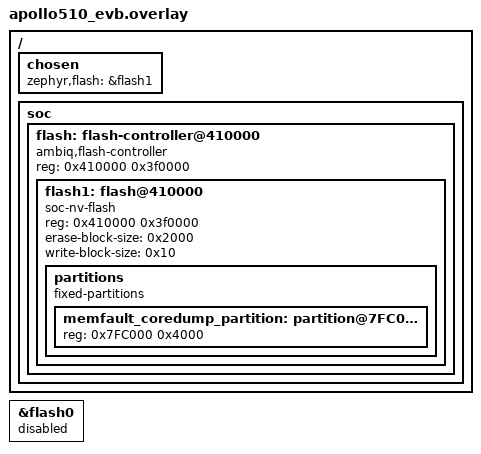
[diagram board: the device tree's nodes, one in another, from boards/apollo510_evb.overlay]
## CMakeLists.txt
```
# Zephyr Example Application

cmake_minimum_required(VERSION 3.20.0)

# The default board for this example is the mps2/an385, but can be
# overridden by passing --board=<board> to west or -DBOARD=<board> to cmake
set(BOARD mps2/an385)

# Select version-specific config overlays before Zephyr is loaded
file(READ "$ENV{ZEPHYR_BASE}/VERSION" _zephyr_version_file)
string(REGEX MATCH "VERSION_MAJOR = ([0-9]+)" _ ${_zephyr_version_file})
set(_zephyr_major ${CMAKE_MATCH_1})
string(REGEX MATCH "VERSION_MINOR = ([0-9]+)" _ ${_zephyr_version_file})
set(_zephyr_minor ${CMAKE_MATCH_1})
string(REGEX MATCH "PATCHLEVEL = ([0-9]+)" _ ${_zephyr_version_file})
set(_zephyr_patch ${CMAKE_MATCH_1})

if("${_zephyr_major}.${_zephyr_minor}.${_zephyr_patch}" VERSION_GREATER_EQUAL "3.4.0")
  set(OVERLAY_CONFIG "${OVERLAY_CONFIG};${CMAKE_CURRENT_SOURCE_DIR}/overlays/zephyr-v3.4.conf")
endif()

find_package(Zephyr REQUIRED HINTS $ENV{ZEPHYR_BASE})

target_sources(app PRIVATE
  src/cdr.c
  src/main.c
  src/metrics.c
)
zephyr_include_directories(config)
project(qemu-app LANGUAGES C VERSION 1.0.0)

# Generate a git hash that's used as part of the software_version, eg
# 1.0.0+12345678. Permit overriding at command line for CI builds.
if (NOT DEFINED ZEPHYR_MEMFAULT_EXAMPLE_GIT_SHA1)
  EXECUTE_PROCESS(
    WORKING_DIRECTORY ${CMAKE_CURRENT_SOURCE_DIR}
    COMMAND git rev-parse --short HEAD
    RESULT_VARIABLE commit_sha1
    OUTPUT_VARIABLE ZEPHYR_MEMFAULT_EXAMPLE_GIT_SHA1
    OUTPUT_STRIP_TRAILING_WHITESPACE
    COMMAND_ERROR_IS_FATAL ANY
  )
endif()

zephyr_compile_definitions(
  ZEPHYR_MEMFAULT_EXAMPLE_GIT_SHA1=\"${ZEPHYR_MEMFAULT_EXAMPLE_GIT_SHA1}\"
)

zephyr_compile_options(--param=min-pagesize=0x1000)

# For Zephyr >=3.0.0,<3.6.0, explicitly enable -Werror
if (${KERNEL_VERSION_MAJOR}.${KERNEL_VERSION_MINOR}.${KERNEL_PATCHLEVEL} VERSION_GREATER_EQUAL 3.0.0 AND
    ${KERNEL_VERSION_MAJOR}.${KERNEL_VERSION_MINOR}.${KERNEL_PATCHLEVEL} VERSION_LESS 3.6.0)
  zephyr_compile_options(-Werror)
endif()
```

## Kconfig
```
# Application Kconfig file
#
# This is loaded when building this directory with west.
menu "Memfault Example Application Configuration"

config ZEPHYR_MEMFAULT_EXAMPLE_AUTO_SETTINGS
    bool
    default y
    # Force on CONFIG_GPIO if the led0 alias is enabled
    select GPIO if $(dt_alias_enabled,led0)
    help
      Non-user-settable configuration options for the example app.

config ZEPHYR_MEMFAULT_EXAMPLE_THREAD_TOGGLE
    bool "Example thread create + abort toggling every 10 seconds"
    default n
    help
      Enables creating and aborting an example thread every 10 seconds in the
      example app

config ZEPHYR_MEMFAULT_EXAMPLE_METRICS
    bool "Use metrics to monitor memory usage and execution time in the example app"
    default y
    depends on MEMFAULT && MEMFAULT_HEAP_STATS
    depends on THREAD_STACK_INFO
    depends on THREAD_RUNTIME_STATS

config ZEPHYR_MEMFAULT_EXAMPLE_SOFTWARE_VERSION
    string "Software Version"
    default "1.0.0"
    help
      The software version to report to Memfault.

# Stub expressions, to support backwards compatibility with older Zephyr
# versions where these options were not available.
config COMPILER_WARNINGS_AS_ERRORS  # v3.6.0+
    bool "Treat warnings as errors"

config CRC  # v3.3.0+
    bool "Cyclic redundancy check (CRC) Support"

config BUILD_OUTPUT_META  # v3.0.0+
    bool "Create a build meta file"

endmenu

source "Kconfig.zephyr"
```

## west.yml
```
# West manifest for Memfault Example Application

manifest:
  self:
    path: qemu-app

  group-filter:
    # Disable the ambiq hal by default; it's compatible only with Zephyr v4.3.0.
    # To enable it, run:
    #   west config manifest.group-filter +ambiq
    #   west update
    - "-ambiq"

  remotes:
    - name: zephyrproject-rtos
      url-base: https://github.com/zephyrproject-rtos
    - name: memfault
      url-base: https://github.com/memfault

  projects:
    - name: zephyr
      remote: zephyrproject-rtos
      revision: v4.4.0
      import:
        # Limit the Zephyr modules to the required set
        name-allowlist:
          - cmsis
          - cmsis_6
          - picolibc
          - hal_ambiq
          - hal_nxp
          - hal_stm32

    # Override the hal_ambiq module to use our patched version, which supports
    # MRAM flash driver on Apollo510
    - name: hal_ambiq
      path: modules/hal/ambiq
      remote: memfault
      revision: zephyr-v4.3.0-apollo510-mram-patch
      groups:
        - ambiq

    - name: memfault-firmware-sdk
      path: modules/lib/memfault-firmware-sdk
      remote: memfault
      # Note: normally this would be pinned to a specific SDK tag instead of
      # master
      revision: master
```

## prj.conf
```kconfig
# This file contains selected Kconfig options for the application.

# Memfault configuration
CONFIG_MEMFAULT=y

# Enable UART console and shell for testing memfault
CONFIG_CONSOLE=y
CONFIG_UART_CONSOLE=y
CONFIG_SHELL=y

# This makes the qemu guest run closer to real time instead of super fast
CONFIG_QEMU_ICOUNT=n

CONFIG_LOG=y
# Using immediate mode to avoid dropping bursts of log messages, eg when running
# `mflt export` to dump base64-chunks to the console
CONFIG_LOG_MODE_IMMEDIATE=y
CONFIG_LOG_BACKEND_UART=y
# Disable shell log output to prevent duplicate logs, since UART backend is
# already enabled. Shell log backend enables later than UART backend, and won't
# show the boot splash messages, so it's simpler to just enable the UART
# backend. Note that the RTT backend is enabled by default- that's ok, and could
# be useful if the board doesn't have a UART available.
CONFIG_SHELL_LOG_BACKEND=n
# Disable logging of printk, to improve 'mflt export' performance under deferred
# logging mode.
CONFIG_LOG_PRINTK=n

# Enable heap stats explicitly. It's enabled by default when heap is enabled,
# see below, but in a default app, it won't be enabled because heap is disabled.
# For this reference example, we select it explicitly.
CONFIG_MEMFAULT_HEAP_STATS=y

# Increase the heap pool and main stack sizes for the example app. Setting a
# non-zero memory pool size is required for heap stats, otherwise there's no
# k_malloc used
CONFIG_HEAP_MEM_POOL_SIZE=4096
CONFIG_MAIN_STACK_SIZE=4096

# Enable Zephyr runtime asserts
CONFIG_ASSERT=y

# Enable Memfault Compact Logs
CONFIG_MEMFAULT_COMPACT_LOG=y

# Enable Memfault self test
CONFIG_MEMFAULT_SHELL_SELF_TEST=y
CONFIG_MEMFAULT_SHELL_SELF_TEST_COREDUMP_STORAGE=y

# Enable emulated RTC driver. Disabled by default because the RTC needs to be
# explicitly updated at runtime to wall clock time, otherwise it will print
# errors.
# CONFIG_RTC=y
# CONFIG_RTC_EMUL=y
# CONFIG_RTC_SHELL=y

# Enable warnings as errors
CONFIG_COMPILER_WARNINGS_AS_ERRORS=y  # v3.6.0+

# Enable Thread run-time stats
CONFIG_THREAD_RUNTIME_STATS=y

# Enable Zephyr CRC implementation, for demonstration purposes only. The
# Memfault SDK provides a built-in CRC-16 implementation used for Memfault chunk
# packets.
CONFIG_CRC=y  # v3.3.0+
```

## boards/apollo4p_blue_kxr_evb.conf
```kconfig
CONFIG_MEMFAULT_COREDUMP_STORAGE_AMBIQ_MRAM=y
```

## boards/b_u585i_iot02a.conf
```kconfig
CONFIG_MEMFAULT_COREDUMP_STORAGE_STM32U5_FLASH=y

# Needed for HWINFO
CONFIG_POWEROFF=y
```

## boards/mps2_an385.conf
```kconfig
CONFIG_MPU_STACK_GUARD=y
CONFIG_WATCHDOG=y
CONFIG_WDOG_CMSDK_APB_START_AT_BOOT=y

# This isn't actually needed- it just adds a reboot in the driver, and we wrap
# the NMI handler anyway, but there is a Kconfig dependency in the CMSDK APB
# watchdog driver so we are forced to include it.
CONFIG_RUNTIME_NMI=y

# Disable the hwinfo module. Enabled by default in the Zephyr port, but there is no
# hwinfo implementation for the QEMU target. Disabling it saves ~100B of code space.
CONFIG_HWINFO=n
```

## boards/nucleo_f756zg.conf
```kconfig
CONFIG_ADC=y
CONFIG_SENSOR=y
```

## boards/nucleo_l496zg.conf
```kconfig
CONFIG_BBRAM=y
CONFIG_BBRAM_SHELL=y
CONFIG_RTC=y
```

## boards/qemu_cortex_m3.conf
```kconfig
CONFIG_STACK_SENTINEL=y

# Disable the hwinfo module. Enabled by default in the Zephyr port, but there is no
# hwinfo implementation for the QEMU target. Disabling it saves ~100B of code space.
CONFIG_HWINFO=n
```

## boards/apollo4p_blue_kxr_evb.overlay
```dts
/*
 Adjust the fixed partitions in flash (MRAM) to add a 'memfault_coredump'
 partition for storing coredumps
*/

&flash0 {
	partitions {
		storage_partition: partition@1e4000 {
			label = "storage";
			reg = < 0x1e4000 0x2000 >;
		};
		memfault_coredump_partition: partition@1e6000 {
			reg = <0x1e6000 0x2000>;
		};
	};
};
```

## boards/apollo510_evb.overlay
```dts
/*
 Adjust the fixed partitions in flash (MRAM) to add a 'memfault_coredump'
 partition for storing coredumps
*/

/*
 Remove the standalone flash0 node, and replace it with a new one set as
 compatible with Ambiq flash driver
*/
&flash0 {
	status = "disabled";
};
/ {
	chosen {
		zephyr,flash = &flash1;
	};
	soc {
		flash: flash-controller@410000 {
			compatible = "ambiq,flash-controller";
			reg = < 0x410000 0x3f0000 >;
			#address-cells = < 0x1 >;
			#size-cells = < 0x1 >;

			flash1: flash@410000 {
				compatible = "soc-nv-flash";
				reg = < 0x410000 0x3f0000 >;
				erase-block-size = < 0x2000 >;
				write-block-size = < 0x10 >;

				partitions {
					compatible = "fixed-partitions";
					#address-cells = < 0x1 >;
					#size-cells = < 0x1 >;

					memfault_coredump_partition: partition@7FC000 {
						reg = < 0x7FC000 0x4000 >;
					};
				};
			};
		};
	};
};
```

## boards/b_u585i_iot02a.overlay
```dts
/*
 Adjust the fixed partitions in internal flash to add a
 'memfault_coredump_partition' for storing coredumps.
*/

&flash0 {
	partitions {
		storage_partition: partition@f0000 {
			label = "storage";
			reg = < 0xf0000 0x2000 >;
		};
		memfault_coredump_partition: partition@f2000 {
			label = "memfault_coredump_partition";
			reg = <0xf2000 0x2000>;
		};
	};
};
```

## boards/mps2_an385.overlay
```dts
/*
    Add emulated RTC device.
*/

/ {
	aliases {
		rtc = &rtc;
	};
	rtc: rtc {
		status = "okay";
		compatible = "zephyr,rtc-emul";
		alarms-count = <2>;
	};
};
```

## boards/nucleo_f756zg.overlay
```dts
/ {
	aliases {
		die-temp0 = &die_temp;
	};
};

&die_temp {
	status = "okay";
};

&adc1 {
	pinctrl-0 = <&adc1_in0_pa0>;
	pinctrl-names = "default";
	st,adc-prescaler = <4>;
	status = "okay";
};
```

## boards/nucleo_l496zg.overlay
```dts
/ {
	aliases {
		backup-register = &bbram;
	};
};

&bbram {
	status = "okay";
};
```

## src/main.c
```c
//! @file
//!
//! Copyright (c) Memfault, Inc.
//! See LICENSE for details
//!
//! Example app main

// clang-format off
#include "memfault/ports/zephyr/include_compatibility.h"
#include <stdlib.h>

#include MEMFAULT_ZEPHYR_INCLUDE(device.h)
#include MEMFAULT_ZEPHYR_INCLUDE(devicetree.h)
#include MEMFAULT_ZEPHYR_INCLUDE(drivers/gpio.h)
#include MEMFAULT_ZEPHYR_INCLUDE(kernel.h)
#include MEMFAULT_ZEPHYR_INCLUDE(logging/log.h)
#include MEMFAULT_ZEPHYR_INCLUDE(shell/shell.h)

#include "cdr.h"
#include "memfault/components.h"
#include "memfault/ports/zephyr/core.h"
// clang-format on

LOG_MODULE_REGISTER(main, LOG_LEVEL_INF);

#if CONFIG_ZEPHYR_MEMFAULT_EXAMPLE_METRICS
  //! Size of memory to allocate on main stack
  //! This requires a larger allocation due to the method used to measure stack usage
  #define STACK_ALLOCATION_SIZE (CONFIG_MAIN_STACK_SIZE >> 2)
  //! Size of memory to allocate on system heap
  #define HEAP_ALLOCATION_SIZE (CONFIG_HEAP_MEM_POOL_SIZE >> 3)
  //! Value to sleep for observing metrics changes
  #define METRICS_OBSERVE_PERIOD MEMFAULT_METRICS_HEARTBEAT_INTERVAL_SECS

//! Array of heap pointers
static void *heap_ptrs[4] = { NULL };
  #if defined(CONFIG_COMMON_LIBC_MALLOC)
    #define MALLOC_ALLOCATION_SIZE (CONFIG_COMMON_LIBC_MALLOC_ARENA_SIZE >> 3)
//! Array of malloc pointers
static void *malloc_ptrs[4] = { NULL };
  #endif

//! Keep a reference to the main thread for stack info
static struct k_thread *s_main_thread = NULL;
#endif  // CONFIG_ZEPHYR_MEMFAULT_EXAMPLE_METRICS

// Blink code taken from the zephyr/samples/basic/blinky example.
static void blink_forever(void) {
#if DT_NODE_HAS_PROP(DT_ALIAS(led0), gpios)
  /* 1000 msec = 1 sec */
  #define SLEEP_TIME_MS 1000

  /* The devicetree node identifier for the "led0" alias. */
  #define LED0_NODE DT_ALIAS(led0)

  static const struct gpio_dt_spec led = GPIO_DT_SPEC_GET(LED0_NODE, gpios);

  int ret = gpio_pin_configure_dt(&led, GPIO_OUTPUT_ACTIVE);
  if (ret < 0) {
    return;
  }

  while (1) {
    gpio_pin_toggle_dt(&led);
    k_msleep(SLEEP_TIME_MS);
  }
#else
  // no led on this board, just sleep forever
  k_sleep(K_FOREVER);
#endif
}

void memfault_platform_get_device_info(sMemfaultDeviceInfo *info) {
  *info = (sMemfaultDeviceInfo){
    .device_serial = "DEMOSERIAL",
    .software_type = "zephyr-app",
    .software_version =
      CONFIG_ZEPHYR_MEMFAULT_EXAMPLE_SOFTWARE_VERSION "+" ZEPHYR_MEMFAULT_EXAMPLE_GIT_SHA1,
    .hardware_version = CONFIG_BOARD,
  };
}

#if CONFIG_ZEPHYR_MEMFAULT_EXAMPLE_THREAD_TOGGLE
K_THREAD_STACK_DEFINE(test_thread_stack_area, 1024);
static struct k_thread test_thread;

static void prv_test_thread_function(void *arg0, void *arg1, void *arg2) {
  ARG_UNUSED(arg0);
  ARG_UNUSED(arg1);
  ARG_UNUSED(arg2);

  k_sleep(K_FOREVER);
}

static void prv_test_thread_work_handler(struct k_work *work) {
  ARG_UNUSED(work);

  static bool started = false;
  if (started) {
    LOG_INF("ending test_thread ❌");
    k_thread_abort(&test_thread);
    started = false;
  } else {
    LOG_INF("starting test_thread ✅");
    k_thread_create(&test_thread, test_thread_stack_area,
                    K_THREAD_STACK_SIZEOF(test_thread_stack_area), prv_test_thread_function, NULL,
                    NULL, NULL, 7, 0, K_FOREVER);
    k_thread_name_set(&test_thread, "test_thread");
    k_thread_start(&test_thread);
    started = true;
  }
}
K_WORK_DEFINE(s_test_thread_work, prv_test_thread_work_handler);

//! Timer handlers run from an ISR so we dispatch the heartbeat job to the
//! worker task
static void prv_test_thread_timer_expiry_handler(struct k_timer *dummy) {
  k_work_submit(&s_test_thread_work);
}
K_TIMER_DEFINE(s_test_thread_timer, prv_test_thread_timer_expiry_handler, NULL);

static void prv_init_test_thread_timer(void) {
  k_timer_start(&s_test_thread_timer, K_SECONDS(10), K_SECONDS(10));

  // fire one time right away
  k_work_submit(&s_test_thread_work);
}
#else
static void prv_init_test_thread_timer(void) { }
#endif  // CONFIG_ZEPHYR_MEMFAULT_EXAMPLE_THREAD_TOGGLE

#if CONFIG_ZEPHYR_MEMFAULT_EXAMPLE_METRICS

  #if defined(CONFIG_INIT_STACKS) && defined(CONFIG_THREAD_STACK_INFO)
//! Helper function to collect metric value on main thread stack usage.
static void prv_collect_main_thread_stack_free(void) {
  if (s_main_thread == NULL) {
    return;
  }

  size_t unused = 0;
  int rc = k_thread_stack_space_get(s_main_thread, &unused);
  if (rc == 0) {
    rc = MEMFAULT_METRIC_SET_UNSIGNED(MainStack_MinBytesFree, unused);
    if (rc) {
      LOG_ERR("Error[%d] setting MainStack_MinBytesFree", rc);
    }
  } else {
    LOG_ERR("Error getting thread stack usage[%d]", rc);
  }
}
  #endif  // defined(CONFIG_INIT_STACKS) && defined(CONFIG_THREAD_STACK_INFO)

static void prv_collect_main_thread_run_stats(void) {
  static uint64_t s_prev_main_thread_cycles = 0;
  static uint64_t s_prev_cpu_all_cycles = 0;

  if (s_main_thread == NULL) {
    return;
  }

  k_thread_runtime_stats_t rt_stats_main = { 0 };
  k_thread_runtime_stats_t rt_stats_all = { 0 };

  k_thread_runtime_stats_get(s_main_thread, &rt_stats_main);
  k_thread_runtime_stats_all_get(&rt_stats_all);

  // Calculate difference since last heartbeat
  uint64_t current_main_thread_cycles = rt_stats_main.execution_cycles - s_prev_main_thread_cycles;
  // Note: execution_cycles = idle + non-idle, total_cycles = non-idle
  uint64_t current_cpu_total_cycles = rt_stats_all.execution_cycles - s_prev_cpu_all_cycles;

  // Calculate percent of main thread execution vs total CPU time. The metric is
  // defined as scaled *10- the value is recorded as percent * 10 (1000), and
  // will be scaled down on ingestion to a float.
  if (current_cpu_total_cycles > 0) {
    uint32_t main_thread_cpu_time = (current_main_thread_cycles * 1000) / current_cpu_total_cycles;
    MEMFAULT_METRIC_SET_UNSIGNED(cpu_usage_main_pct, main_thread_cpu_time);
  }

  // Update previous values
  s_prev_main_thread_cycles = current_main_thread_cycles;
  s_prev_cpu_all_cycles = current_cpu_total_cycles;
}

//! Shell function to exercise example memory metrics
//!
//! This function demonstrates the change in stack and heap memory metrics
//! as memory is allocated and deallocated from these regions.
//!
//! @warning This code uses `memfault_metrics_heartbeat_debug_trigger` which is not intended
//! to be used in production code. This functions use here is solely to demonstrate the metrics
//! values changing. Production applications should rely on the heartbeat timer to trigger
//! collection
static int prv_run_example_memory_metrics(const struct shell *shell, size_t argc, char **argv) {
  ARG_UNUSED(shell);
  ARG_UNUSED(argc);
  ARG_UNUSED(argv);

  if (s_main_thread == NULL) {
    return 0;
  }

  // Next two loops demonstrate heap usage metrics
  for (size_t i = 0; i < ARRAY_SIZE(heap_ptrs); i++) {
    heap_ptrs[i] = k_malloc(HEAP_ALLOCATION_SIZE);
  }
  #if defined(CONFIG_COMMON_LIBC_MALLOC)
  for (size_t i = 0; i < ARRAY_SIZE(malloc_ptrs); i++) {
    malloc_ptrs[i] = malloc(MALLOC_ALLOCATION_SIZE);
  }
  #endif

  // Collect data after allocation
  memfault_metrics_heartbeat_debug_trigger();

  for (size_t i = 0; i < ARRAY_SIZE(heap_ptrs); i++) {
    k_free(heap_ptrs[i]);
    heap_ptrs[i] = NULL;
  }
  #if defined(CONFIG_COMMON_LIBC_MALLOC)
  for (size_t i = 0; i < ARRAY_SIZE(malloc_ptrs); i++) {
    free(malloc_ptrs[i]);
    malloc_ptrs[i] = NULL;
  }
  #endif

  // Collect data after deallocation
  memfault_metrics_heartbeat_debug_trigger();
  return 0;
}

SHELL_CMD_REGISTER(memory_metrics, NULL, "Collects runtime memory metrics from application",
                   prv_run_example_memory_metrics);

  #if defined(CONFIG_INIT_STACKS) && defined(CONFIG_THREAD_STACK_INFO)
//! Callback to collect stack usage for specific threads
static void prv_collect_thread_stack_usage_cb(const struct k_thread *thread, void *user_data) {
  // table mapping thread names to metric IDs
  static const struct {
    const char *name;
    MemfaultMetricId id;
  } threads[] = {
    { "shell_uart", MEMFAULT_METRICS_KEY(shell_uart_stack_free_bytes) },
  };

  // scan for a matching thread name
  for (size_t i = 0; i < ARRAY_SIZE(threads); i++) {
    if (strncmp(thread->name, threads[i].name, CONFIG_THREAD_MAX_NAME_LEN) == 0) {
      // get the stack usage and record in the matching metric id
      size_t stack_free_bytes;
      k_thread_stack_space_get(thread, &stack_free_bytes);
      memfault_metrics_heartbeat_set_unsigned(threads[i].id, stack_free_bytes);
    }
  }
}
  #endif  // defined(CONFIG_INIT_STACKS) && defined(CONFIG_THREAD_STACK_INFO)

// Override function to collect the app metric MainStack_MinBytesFree
// and print current metric values
void memfault_metrics_heartbeat_collect_data(void) {
  prv_collect_main_thread_run_stats();

  #if defined(CONFIG_INIT_STACKS) && defined(CONFIG_THREAD_STACK_INFO)
  prv_collect_main_thread_stack_free();
  k_thread_foreach(prv_collect_thread_stack_usage_cb, NULL);
  #endif

  memfault_metrics_heartbeat_debug_print();
}

//! Helper function to demonstrate changes in stack metrics
static void prv_run_stack_metrics_example(void) {
  volatile uint8_t stack_array[STACK_ALLOCATION_SIZE];
  memset((uint8_t *)stack_array, 0, STACK_ALLOCATION_SIZE);
}
#endif  // CONFIG_ZEPHYR_MEMFAULT_EXAMPLE_METRICS

#if defined(CONFIG_MEMFAULT_FAULT_HANDLER_RETURN)
  #include MEMFAULT_ZEPHYR_INCLUDE(fatal.h)
void k_sys_fatal_error_handler(unsigned int reason, const z_arch_esf_t *esf) {
  printk("User fatal handler invoked with reason: %d. Rebooting!\n", reason);
  memfault_platform_reboot();
}
#endif

static int prv_metrics_session(const struct shell *shell, size_t argc, char **argv) {
  const char *cmd_name_string = "UNKNOWN";
  if (argc > 1) {
    cmd_name_string = argv[1];
  }

  shell_print(shell, "Executing a test metrics session named 'cli'\n");

  MEMFAULT_METRICS_SESSION_START(cli);
  // API v1
  // MEMFAULT_METRIC_SET_STRING(cli_cmd_name, cmd_name_string);
  // API v2
  MEMFAULT_METRIC_SESSION_SET_STRING(cmd_name, cli, cmd_name_string);
  MEMFAULT_METRICS_SESSION_END(cli);

  return 0;
}

SHELL_CMD_REGISTER(metrics_session, NULL, "Trigger a one-time metrics session for testing",
                   prv_metrics_session);

static int prv_session_crash(const struct shell *shell, size_t argc, char **argv) {
  ARG_UNUSED(shell);
  ARG_UNUSED(argc);
  ARG_UNUSED(argv);

  LOG_ERR("Triggering crash");

  MEMFAULT_METRICS_SESSION_START(cli);

  MEMFAULT_ASSERT(0);

  return 0;
}

SHELL_CMD_REGISTER(session_crash, NULL, "session crash", prv_session_crash);

#if defined(CONFIG_BBRAM)
  #include <zephyr/drivers/bbram.h>

void memfault_reboot_tracking_load(sMemfaultRebootTrackingStorage *dst) {
  // restore reboot tracking from bbram_read

  // clear the destination buffer- if the bbram restore doesn't work, we won't
  // have reboot tracking data.
  memset(dst, 0, sizeof(*dst));

  const struct device *const dev = DEVICE_DT_GET(DT_NODELABEL(bbram));
  for (size_t i = 0; i < sizeof(*dst) / 4; i++) {
    bbram_read(dev, 4 * i, 4, &dst->data[4 * i]);
  }
}

void memfault_reboot_tracking_save(const sMemfaultRebootTrackingStorage *src) {
  // now back up reboot tracking to RTC backup regs
  const struct device *const dev = DEVICE_DT_GET(DT_NODELABEL(bbram));
  for (size_t i = 0; i < sizeof(*src) / 4; i++) {
    bbram_write(dev, 4 * i, 4, &src->data[4 * i]);
  }
}
#endif  // defined(CONFIG_BBRAM)

static int prv_log_overflow(const struct shell *shell, size_t argc, char **argv) {
  // get log line count from command line
  int log_line_count = 0;
  if (argc > 1) {
    log_line_count = strtoul(argv[1], NULL, 0);
  }

  for (int i = 0; i < log_line_count; i++) {
    LOG_INF("Log line %d", i);
  }

  shell_print(shell, "Dropped/recorded log lines: %d/%d", memfault_log_get_dropped_count(),
              memfault_log_get_recorded_count());

  return 0;
}

SHELL_CMD_REGISTER(log_overflow, NULL, "generate a number of log lines", prv_log_overflow);

#include "memfault/core/heap_stats_impl.h"
static int prv_calloc_test(const struct shell *shell, size_t argc, char **argv) {
  (void)argc;
  (void)argv;
  shell_print(shell, "before: in_use=%u max_in_use=%u", g_memfault_heap_stats.in_use_block_count,
              g_memfault_heap_stats.max_in_use_block_count);
  void *ptr = k_calloc(4, 16);
  shell_print(shell, "k_calloc(4, 16) -> %p", ptr);
  shell_print(shell, "after: in_use=%u max_in_use=%u", g_memfault_heap_stats.in_use_block_count,
              g_memfault_heap_stats.max_in_use_block_count);
  k_free(ptr);
  return 0;
}
SHELL_CMD_REGISTER(calloc_test, NULL, "temp test of k_calloc heap stats tracking", prv_calloc_test);

#if !defined(CONFIG_MEMFAULT_CRC16_BUILTIN)
  #include MEMFAULT_ZEPHYR_INCLUDE(sys/crc.h)

uint16_t memfault_crc16_compute(uint16_t crc_initial_value, const void *data,
                                size_t data_len_bytes) {
  return crc16_itu_t(crc_initial_value, data, data_len_bytes);
}
#endif

#if defined(CONFIG_MEMFAULT_PLATFORM_TIME_SINCE_BOOT_CUSTOM)
uint64_t memfault_platform_get_time_since_boot_ms(void) {
  // Simple custom implementation, identical to the default one, to demonstrate
  // how to override the time since boot function.
  return k_uptime_get();
}
#endif

#if defined(CONFIG_WDOG_CMSDK_APB_START_AT_BOOT)
  #include MEMFAULT_ZEPHYR_INCLUDE(drivers/watchdog.h)
// Watchdog feed timer
static void prv_watchdog_feed_timer_handler(struct k_timer *dummy) {
  ARG_UNUSED(dummy);
  const struct device *const wdt = DEVICE_DT_GET(DT_ALIAS(watchdog0));
  // the CMSDK WDOG doesn't use a channel, pass 0
  wdt_feed(wdt, 0);
}
K_TIMER_DEFINE(s_watchdog_feed_timer, prv_watchdog_feed_timer_handler, NULL);

static int prv_start_watchdog_feed_timer() {
  // Start the watchdog feed timer to prevent the watchdog from resetting the system
  k_timer_start(&s_watchdog_feed_timer, K_MSEC(100), K_MSEC(100));
  return 0;
}

SYS_INIT(prv_start_watchdog_feed_timer, APPLICATION, CONFIG_KERNEL_INIT_PRIORITY_DEFAULT);
#endif  // CONFIG_WDOG_CMSDK_APB_START_AT_BOOT

int main(void) {
  LOG_INF("👋 Memfault Demo App! Board %s\n", CONFIG_BOARD);
  memfault_device_info_dump();

  memfault_cdr_register_source(&g_custom_data_recording_source);

#if !defined(CONFIG_MEMFAULT_RECORD_REBOOT_ON_SYSTEM_INIT)
  memfault_zephyr_collect_reset_info();
#endif

#if CONFIG_ZEPHYR_MEMFAULT_EXAMPLE_METRICS
  s_main_thread = k_current_get();

  // @warning This code uses `memfault_metrics_heartbeat_debug_trigger` which is not intended
  // to be used in production code. This functions use here is solely to demonstrate the metrics
  // values changing. Production applications should rely on the heartbeat timer to trigger
  // collection

  // Collect a round of metrics to show initial stack usage
  memfault_metrics_heartbeat_debug_trigger();

  prv_run_stack_metrics_example();

  // Collect another round to show change in stack metrics
  memfault_metrics_heartbeat_debug_trigger();
#endif

  prv_init_test_thread_timer();

  blink_forever();

  return 0;
}
```

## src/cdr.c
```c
//! @file
//!
//! Copyright (c) Memfault, Inc.
//! See LICENSE for details
//!
//! Sample CDR implementation. See https://mflt.io/custom-data-recordings for
//! more information

// clang-format off
#include "memfault/ports/zephyr/include_compatibility.h"

#include MEMFAULT_ZEPHYR_INCLUDE(logging/log.h)
#include MEMFAULT_ZEPHYR_INCLUDE(shell/shell.h)

#include "memfault/components.h"
// clang-format on

LOG_MODULE_REGISTER(cdr);

// Only read the CDR payload when this is set
static bool s_cdr_ready_to_send = false;
// keep track of the offset into the CDR data; the packetizer may call
// repeatedly depending on chunk size constraints
static size_t s_cdr_read_offset = 0;

// set of MIME types for this payload
static const char *mimetypes[] = { MEMFAULT_CDR_TEXT };

// the actual payload is just a simple string in this example
static const char cdr_payload[] = "hello cdr!";

// the CDR metadata structure
static sMemfaultCdrMetadata s_cdr_metadata = {
  .start_time = {
    .type = kMemfaultCurrentTimeType_Unknown,
  },
  .mimetypes = mimetypes,
  .num_mimetypes = MEMFAULT_ARRAY_SIZE(mimetypes),

  // in this case, the data size is fixed. typically it would be set in the
  // prv_has_cdr_cb() function, and likely variable size
  .data_size_bytes = sizeof(cdr_payload) - 1,
  .duration_ms = 0,

  .collection_reason = "example cdr upload",
};

// called to see if there's any data available; uses the *metadata output to set
// the header fields in the chunked message sent to Memfault
static bool prv_has_cdr_cb(sMemfaultCdrMetadata *metadata) {
  *metadata = s_cdr_metadata;
  return s_cdr_ready_to_send;
}

// called by the packetizer to read up to .data_size_bytes of CDR data
static bool prv_read_data_cb(uint32_t offset, void *data, size_t data_len) {
  if (offset != s_cdr_read_offset) {
    LOG_ERR("Unexpected offset: %d vs %d", offset, s_cdr_read_offset);
    s_cdr_read_offset = 0;
    return false;
  }

  const size_t copy_len = MEMFAULT_MIN(data_len, sizeof(cdr_payload) - offset);
  LOG_INF("Reading %d bytes from offset %d", copy_len, offset);

  memcpy(data, ((uint8_t *)cdr_payload) + offset, copy_len);
  s_cdr_read_offset += copy_len;
  return true;
}

// called when all data has been drained from the read callback
static void prv_mark_cdr_read_cb(void) {
  s_cdr_ready_to_send = false;
  // only reset this offset when the data has been read
  s_cdr_read_offset = 0;
}

// Set up the callback functions. This CDR Source Implementation structure must
// have a lifetime through the duration of the program- typically setting it to
// 'const' is appropriate
const sMemfaultCdrSourceImpl g_custom_data_recording_source = {
  .has_cdr_cb = prv_has_cdr_cb,
  .read_data_cb = prv_read_data_cb,
  .mark_cdr_read_cb = prv_mark_cdr_read_cb,
};

//! Shell function to stage a sample CDR payload for collection next time
//! the packetizer runs
static int prv_stage_cdr(const struct shell *shell, size_t argc, char **argv) {
  ARG_UNUSED(shell);
  ARG_UNUSED(argc);
  ARG_UNUSED(argv);

  s_cdr_ready_to_send = true;
  s_cdr_read_offset = 0;

  sMemfaultCurrentTime timestamp;
  if (memfault_platform_time_get_current(&timestamp)) {
    s_cdr_metadata.start_time = timestamp;
  } else {
    s_cdr_metadata.start_time.type = kMemfaultCurrentTimeType_Unknown;
  }

  return 0;
}

SHELL_CMD_REGISTER(cdr, NULL, "Stages a sample CDR payload", prv_stage_cdr);
```

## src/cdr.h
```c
#pragma once

//! @file
//!
//! Copyright (c) Memfault, Inc.
//! See LICENSE for details
//!
//! Sample CDR implementation. See https://mflt.io/custom-data-recordings for
//! more information

#include "memfault/components.h"

//! Defined by the module, must be registered with the Memfault SDK on system
//! initialization.
extern const sMemfaultCdrSourceImpl g_custom_data_recording_source;
```

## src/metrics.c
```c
//! @file
//!
//! Copyright (c) Memfault, Inc.
//! See LICENSE for details
//!
//! Metrics for QEMU sample app.

#if defined(CONFIG_MEMFAULT_METRICS_THREADS)

  #include "memfault/ports/zephyr/thread_metrics.h"

//! Set the list of threads to monitor for stack usage
MEMFAULT_METRICS_DEFINE_THREAD_METRICS(
  #if defined(CONFIG_MEMFAULT_METRICS_THREADS_DEFAULTS)
  {
    .thread_name = "idle",
    .stack_usage_metric_key = MEMFAULT_METRICS_KEY(memory_idle_pct_max),
  },
  {
    .thread_name = "sysworkq",
    .stack_usage_metric_key = MEMFAULT_METRICS_KEY(memory_sysworkq_pct_max),
  },
  #endif
  {
    .thread_name = "main",
    .stack_usage_metric_key = MEMFAULT_METRICS_KEY(memory_main_pct_max),
  },
  {
    .thread_name = "shell_uart",
    .stack_usage_metric_key = MEMFAULT_METRICS_KEY(memory_shell_uart_pct_max),
  });
#endif  // CONFIG_MEMFAULT_METRICS_THREADS
```
